# NUC505_v1 register map
File version: 1.0
Registers are 32-bit, read-write, reset 0x0 unless marked. A register's access mark holds for its fields unless they carry their own. Offsets are from the block's base; [hi:lo] are bit positions.

## WDT — WDT Register Map
Base 0x400EF000
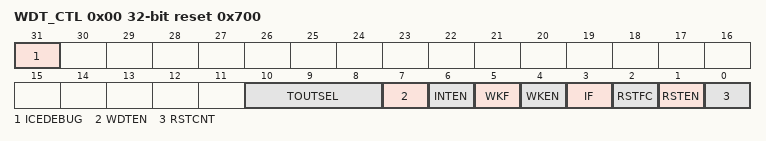
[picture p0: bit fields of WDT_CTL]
0x00 WDT_CTL reset 0x700 — Watchdog Timer Control Register
  [31] ICEDEBUG — ICE Debug Mode Acknowledge Disable Control. Watchdog Timer counter will keep going no matter CPU is held by ICE or not.
    0=ICE debug mode acknowledgement affects Watchdog Timer counting; 1=ICE debug mode acknowledgement Disabled
  [10:8] TOUTSEL — Watchdog Timer Time-out Interval Selection. These three bits select the time-out interval period for the Watchdog Timer.
    0=24 *TWDT; 1=26 *TWDT; 2=28 *TWDT; 3=210 *TWDT; 4=212 *TWDT; 5=214 *TWDT; 6=216 *TWDT; 7=218 *TWDT
  [7] WDTEN — Watchdog Timer Enable Control
    0=Watchdog Timer Disabled (This action will reset the internal counter); 1=Watchdog Timer Enabled
  [6] INTEN — Watchdog Timer Interrupt Enable Control. If this bit is enabled, the Watchdog Timer time-out interrupt signal is generated and inform to CPU.
    0=Watchdog Timer interrupt Disabled; 1=Watchdog Timer interrupt Enabled
  [5] WKF — Watchdog Timer Wake-up Flag. This bit indicates the interrupt wake-up flag status of Watchdog Timer. Note: This bit is cleared by writing 1 to it.
    0=Watchdog Timer does not cause chip wake-up; 1=Chip wake-up from Power-down if Watchdog Timer time-out interrupt signal generated
  [4] WKEN — Watchdog Timer Wake-up Function Enable Control. If this bit is set to 1, while Watchdog Timer interrupt flag IF (WDT_CTL[3]) is generated to 1 and INTEN (WDT_CTL[6] Watchdog Timer interrupt enable) is enabled, the Watchdog Timer time-out interrupt signal will generate a wake-up trigger event to chip. Note: Chip can be woken-up by Watchdog Timer time-out interrupt signal generated only if Watchdog Timer clock source is selected to 32 kHz oscillator.
    0=Wake-up trigger event Disabled if Watchdog Timer time-out interrupt signal generated; 1=Wake-up trigger event Enabled if Watchdog Timer time-out interrupt signal generated
  [3] IF — Watchdog Timer Interrupt Flag. This bit will set to 1 while Watchdog Timer counter value reaches the selected Watchdog Timer time-out interval. Note: This bit is cleared by writing 1 to it.
    0=Watchdog Timer time-out interrupt did not occur; 1=Watchdog Timer time-out interrupt occurred
  [2] RSTFC — Watchdog Timer Reset Flag Cleared. Write 1 to clear the RSTF (WDT_RSTSTS [2]).
  [1] RSTEN — Watchdog Timer Reset Enable Control. Setting this bit will enable the Watchdog Timer time-out reset function If the Watchdog Timer counter value has not been cleared after the specific Watchdog Timer reset delay period expires.
    0=Watchdog Timer time-out reset function Disabled; 1=Watchdog Timer time-out reset function Enabled
  [0] RSTCNT — Clear Watchdog Timer. Note: This bit will be automatically cleared by hardware.
    0=No effect; 1=Reset the internal 18-bit Watchdog Timer counter
0x04 WDT_ALTCTL — Watchdog Timer Alternative Control Register
  [1:0] RSTDSEL — Watchdog Timer Reset Delay Selection. When Watchdog Timer time-out happened, software has a time named Watchdog Timer reset delay period to clear Watchdog Timer counter to prevent Watchdog Timer time-out reset happened. Software can select a suitable value of Watchdog Timer reset delay period for different Watchdog Timer time-out period. Note: This bit will be reset to 0 if Watchdog Timer time-out reset happened.
    0=Watchdog Timer reset delay period is (1024+2) * WDT_CLK; 1=Watchdog Timer reset delay period is (128+2) * WDT_CLK; 2=Watchdog Timer reset delay period is (16+2) * WDT_CLK; 3=Watchdog Timer reset delay period is (1+2) * WDT_CLK
0x10 WDT_RSTSTS ro reset 0x700 — Watchdog Timer Reset Status Register
  [2] RSTF — Watchdog Timer Reset Flag. This bit indicates the system has been reset by Watchdog Timer time-out reset or not. Note: This bit is cleared by writing 1 to RSTFC (WDT_CTL [2]).
    0=Watchdog Timer time-out reset did not occur; 1=Watchdog Timer time-out reset occurred
